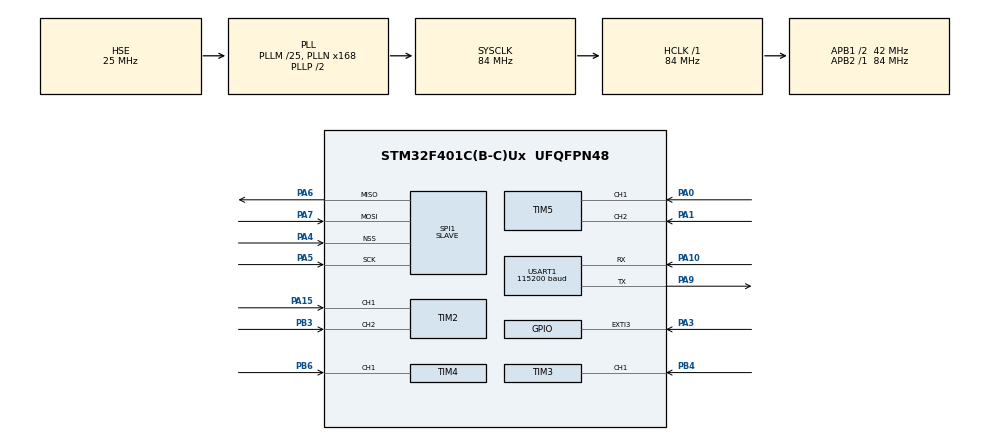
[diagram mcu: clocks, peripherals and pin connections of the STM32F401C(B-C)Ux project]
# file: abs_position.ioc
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Mcu.Family=STM32F4
Mcu.Name=STM32F401C(B-C)Ux
Mcu.Package=UFQFPN48
NVIC.EXTI3_IRQn=true\:0\:0\:false\:false\:true\:true\:true\:true
NVIC.PriorityGroup=NVIC_PRIORITYGROUP_4
NVIC.SPI1_IRQn=true\:0\:0\:false\:false\:true\:true\:true\:true
NVIC.TIM1_UP_TIM10_IRQn=true\:0\:0\:false\:false\:true\:true\:true\:true
PA0-WKUP.GPIO_PuPd=GPIO_PULLUP
PA0-WKUP.GPIO_Speed=GPIO_SPEED_FREQ_MEDIUM
PA0-WKUP.Signal=S_TIM5_CH1
PA1.GPIO_PuPd=GPIO_PULLUP
PA1.GPIO_Speed=GPIO_SPEED_FREQ_MEDIUM
PA1.Signal=S_TIM5_CH2
PA10.Mode=Asynchronous
PA10.Signal=USART1_RX
PA15.GPIO_PuPd=GPIO_PULLUP
PA15.GPIO_Speed=GPIO_SPEED_FREQ_MEDIUM
PA15.Signal=S_TIM2_CH1_ETR
PA3.GPIO_ModeDefaultEXTI=GPIO_MODE_IT_FALLING
PA3.Signal=GPXTI3
PA4.Mode=NSS_Signal_Hard_Input
PA4.Signal=SPI1_NSS
PA5.GPIO_Speed=GPIO_SPEED_FREQ_VERY_HIGH
PA5.Mode=Full_Duplex_Slave
PA5.Signal=SPI1_SCK
PA6.GPIO_PuPd=GPIO_NOPULL
PA6.GPIO_Speed=GPIO_SPEED_FREQ_VERY_HIGH
PA6.Mode=Full_Duplex_Slave
PA6.Signal=SPI1_MISO
PA7.Mode=Full_Duplex_Slave
PA7.Signal=SPI1_MOSI
PA9.Mode=Asynchronous
PA9.Signal=USART1_TX
PB3.GPIO_PuPd=GPIO_PULLUP
PB3.GPIO_Speed=GPIO_SPEED_FREQ_MEDIUM
PB3.Signal=S_TIM2_CH2
PB4.Signal=S_TIM3_CH1
PB6.Signal=S_TIM4_CH1
PH0\ -\ OSC_IN.Mode=HSE-External-Oscillator
PH0\ -\ OSC_IN.Signal=RCC_OSC_IN
PH1\ -\ OSC_OUT.Mode=HSE-External-Oscillator
PH1\ -\ OSC_OUT.Signal=RCC_OSC_OUT
ProjectManager.HeapSize=0xf000
ProjectManager.StackSize=0x400
ProjectManager.TargetToolchain=STM32CubeIDE
RCC.48MHZClocksFreq_Value=42000000
RCC.AHBFreq_Value=84000000
RCC.APB1CLKDivider=RCC_HCLK_DIV2
RCC.APB1Freq_Value=42000000
RCC.APB1TimFreq_Value=84000000
RCC.APB2Freq_Value=84000000
RCC.APB2TimFreq_Value=84000000
RCC.CortexFreq_Value=84000000
RCC.HCLKFreq_Value=84000000
RCC.HSE_VALUE=25000000
RCC.HSI_VALUE=16000000
RCC.LSE_VALUE=32768
RCC.PLLM=25
RCC.PLLN=168
RCC.PLLSourceVirtual=RCC_PLLSOURCE_HSE
RCC.SYSCLKFreq_VALUE=84000000
RCC.SYSCLKSource=RCC_SYSCLKSOURCE_PLLCLK
RCC.VCOOutputFreq_Value=168000000
SH.S_TIM2_CH1_ETR.0=TIM2_CH1,Encoder_Interface
SH.S_TIM2_CH2.0=TIM2_CH2,Encoder_Interface
SH.S_TIM3_CH1.0=TIM3_CH1,TriggerSource_TI1FP1
SH.S_TIM4_CH1.0=TIM4_CH1,TriggerSource_TI1FP1
SH.S_TIM5_CH1.0=TIM5_CH1,Encoder_Interface
SH.S_TIM5_CH2.0=TIM5_CH2,Encoder_Interface
SPI1.Direction=SPI_DIRECTION_2LINES
SPI1.Mode=SPI_MODE_SLAVE
SPI1.VirtualNSS=VM_NSSHARD
SPI1.VirtualType=VM_SLAVE
TIM1.Period=(10000/4)-1
TIM1.Prescaler=8400-1
TIM1.TIM_MasterOutputTrigger=TIM_TRGO_UPDATE
TIM1.TIM_MasterSlaveMode=TIM_MASTERSLAVEMODE_ENABLE
TIM2.ClockDivision=TIM_CLOCKDIVISION_DIV1
TIM2.EncoderMode=TIM_ENCODERMODE_TI12
TIM2.IC1Filter=15
TIM2.IC1Polarity=TIM_ICPOLARITY_FALLING
TIM2.IC2Filter=15
TIM2.IC2Polarity=TIM_ICPOLARITY_FALLING
TIM3.Slave_TriggerFilter=15
TIM3.Slave_TriggerPolarity=TIM_TRIGGERPOLARITY_FALLING
TIM4.Slave_TriggerFilter=15
TIM4.Slave_TriggerPolarity=TIM_TRIGGERPOLARITY_FALLING
TIM5.EncoderMode=TIM_ENCODERMODE_TI12
TIM5.IC1Filter=15
TIM5.IC1Polarity=TIM_ICPOLARITY_FALLING
TIM5.IC2Filter=15
TIM5.IC2Polarity=TIM_ICPOLARITY_FALLING
USART1.BaudRate=115200
USART1.OverSampling=UART_OVERSAMPLING_16
USART1.VirtualMode=VM_ASYNC
VP_TIM1_VS_ClockSourceINT.Mode=Internal
VP_TIM3_VS_ControllerModeClock.Mode=Clock Mode
VP_TIM4_VS_ControllerModeClock.Mode=Clock Mode
board=custom

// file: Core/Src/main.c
/* USER CODE BEGIN Header */
/**
  ******************************************************************************
  * @file           : main.c
  * @brief          : Main program body
  ******************************************************************************
  * @attention
  *
  * Copyright (c) 2025 STMicroelectronics.
  * All rights reserved.
  *
  * This software is licensed under terms that can be found in the LICENSE file
  * in the root directory of this software component.
  * If no LICENSE file comes with this software, it is provided AS-IS.
  *
  ******************************************************************************
  */
/* USER CODE END Header */
#include "main.h"
#include "spi.h"
#include "tim.h"
#include "usart.h"
#include "gpio.h"

void SystemClock_Config(void);

int main(void)
{

  /* MCU Configuration--------------------------------------------------------*/

  /* Reset of all peripherals, Initializes the Flash interface and the Systick. */
  HAL_Init();

  /* Configure the system clock */
  SystemClock_Config();

  /* Initialize all configured peripherals */
  MX_GPIO_Init();
  MX_TIM2_Init();
  MX_TIM5_Init();
  MX_SPI1_Init();
  MX_USART1_UART_Init();
  MX_TIM1_Init();
  MX_TIM3_Init();
  MX_TIM4_Init();
  /* USER CODE BEGIN 2 */
  machine_init();
  /* USER CODE END 2 */

  /* Infinite loop */
  while (1)
  {

  }
}

void SystemClock_Config(void)
{
  RCC_OscInitTypeDef RCC_OscInitStruct = {0};
  RCC_ClkInitTypeDef RCC_ClkInitStruct = {0};

  /** Configure the main internal regulator output voltage
  */
  __HAL_RCC_PWR_CLK_ENABLE();
  __HAL_PWR_VOLTAGESCALING_CONFIG(PWR_REGULATOR_VOLTAGE_SCALE2);

  /** Initializes the RCC Oscillators according to the specified parameters
  * in the RCC_OscInitTypeDef structure.
  */
  RCC_OscInitStruct.OscillatorType = RCC_OSCILLATORTYPE_HSE;
  RCC_OscInitStruct.HSEState = RCC_HSE_ON;
  RCC_OscInitStruct.PLL.PLLState = RCC_PLL_ON;
  RCC_OscInitStruct.PLL.PLLSource = RCC_PLLSOURCE_HSE;
  RCC_OscInitStruct.PLL.PLLM = 25;
  RCC_OscInitStruct.PLL.PLLN = 168;
  RCC_OscInitStruct.PLL.PLLP = RCC_PLLP_DIV2;
  RCC_OscInitStruct.PLL.PLLQ = 4;
  if (HAL_RCC_OscConfig(&RCC_OscInitStruct) != HAL_OK)
  {
    Error_Handler();
  }

  /** Initializes the CPU, AHB and APB buses clocks
  */
  RCC_ClkInitStruct.ClockType = RCC_CLOCKTYPE_HCLK|RCC_CLOCKTYPE_SYSCLK
                              |RCC_CLOCKTYPE_PCLK1|RCC_CLOCKTYPE_PCLK2;
  RCC_ClkInitStruct.SYSCLKSource = RCC_SYSCLKSOURCE_PLLCLK;
  RCC_ClkInitStruct.AHBCLKDivider = RCC_SYSCLK_DIV1;
  RCC_ClkInitStruct.APB1CLKDivider = RCC_HCLK_DIV2;
  RCC_ClkInitStruct.APB2CLKDivider = RCC_HCLK_DIV1;

  if (HAL_RCC_ClockConfig(&RCC_ClkInitStruct, FLASH_LATENCY_2) != HAL_OK)
  {
    Error_Handler();
  }
}

void Error_Handler(void)
{
  __disable_irq();
  while (1)
  {
  }
}
